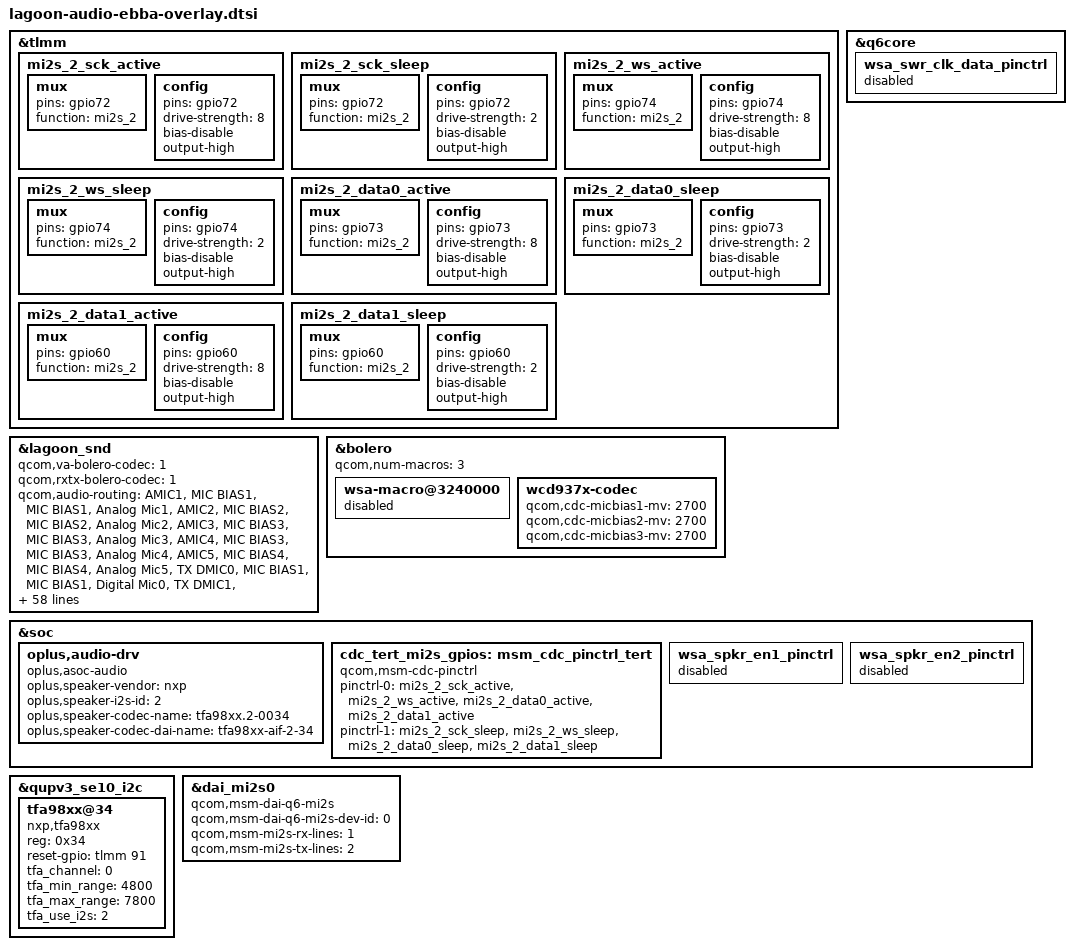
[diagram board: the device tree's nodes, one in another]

&tlmm {
		/* #ifdef OPLUS_ARCH_EXTENDS */
		mi2s_2_sck_active: mi2s_2_sck_active {
			mux {
					pins = "gpio72";
					function = "mi2s_2";
				};

				config {
					pins = "gpio72";
					drive-strength = <8>;	/* 8 mA */
					bias-disable;
					output-high;
				};
		};

		mi2s_2_sck_sleep: mi2s_2_sck_sleep {
			mux {
					pins = "gpio72";
					function = "mi2s_2";
				};

				config {
					pins = "gpio72";
					drive-strength = <2>;	/* 2 mA */
					bias-disable;
					output-high;
				};
		};

		mi2s_2_ws_active: mi2s_2_ws_active {
			mux {
					pins = "gpio74";
					function = "mi2s_2";
				};

				config {
					pins = "gpio74";
					drive-strength = <8>;	/* 8 mA */
					bias-disable;
					output-high;
				};
		};

		mi2s_2_ws_sleep: mi2s_2_ws_sleep {
			mux {
					pins = "gpio74";
					function = "mi2s_2";
				};

				config {
					pins = "gpio74";
					drive-strength = <2>;	/* 8 mA */
					bias-disable;
					output-high;
				};
		};

		mi2s_2_data0_active: mi2s_2_data0_active {
			mux {
					pins = "gpio73";
					function = "mi2s_2";
				};

				config {
					pins = "gpio73";
					drive-strength = <8>;	/* 8 mA */
					bias-disable;
					output-high;
				};
		};

		mi2s_2_data0_sleep: mi2s_2_data0_sleep {
			mux {
					pins = "gpio73";
					function = "mi2s_2";
				};

				config {
					pins = "gpio73";
					drive-strength = <2>;	/* 8 mA */
					bias-disable;
					output-high;
				};
		};

		mi2s_2_data1_active: mi2s_2_data1_active {
			mux {
					pins = "gpio60";
					function = "mi2s_2";
				};

				config {
					pins = "gpio60";
					drive-strength = <8>;	/* 8 mA */
					bias-disable;
					output-high;
				};
		};

		mi2s_2_data1_sleep: mi2s_2_data1_sleep {
			mux {
					pins = "gpio60";
					function = "mi2s_2";
				};

				config {
					pins = "gpio60";
					drive-strength = <2>;	/* 8 mA */
					bias-disable;
					output-high;
				};
		};
		//#endif /* OPLUS_ARCH_EXTENDS */
};

&q6core {
        wsa_swr_clk_data_pinctrl {
                status = "disabled";
        };
};

&lagoon_snd {
	qcom,va-bolero-codec = <1>;
	qcom,rxtx-bolero-codec = <1>;
	qcom,audio-routing =
		"AMIC1", "MIC BIAS1",
		"MIC BIAS1", "Analog Mic1",
		"AMIC2", "MIC BIAS2",
		"MIC BIAS2", "Analog Mic2",
		"AMIC3", "MIC BIAS3",
		"MIC BIAS3", "Analog Mic3",
		"AMIC4", "MIC BIAS3",
		"MIC BIAS3", "Analog Mic4",
		"AMIC5", "MIC BIAS4",
		"MIC BIAS4", "Analog Mic5",
		"TX DMIC0", "MIC BIAS1",
		"MIC BIAS1", "Digital Mic0",
		"TX DMIC1", "MIC BIAS1",
		"MIC BIAS1", "Digital Mic1",
		"TX DMIC2", "MIC BIAS3",
		"MIC BIAS3", "Digital Mic2",
		"TX DMIC3", "MIC BIAS3",
		"MIC BIAS3", "Digital Mic3",
		"TX DMIC4", "MIC BIAS4",
		"MIC BIAS4", "Digital Mic4",
		"TX DMIC5", "MIC BIAS4",
		"MIC BIAS4", "Digital Mic5",
		"IN1_HPHL", "HPHL_OUT",
		"IN2_HPHR", "HPHR_OUT",
		"IN3_AUX", "AUX_OUT",
		"TX SWR_ADC0", "ADC1_OUTPUT",
		//#ifdef OPLUS_ARCH_EXTENDS
		//for tfa98xx i2s
		"TX SWR_ADC2", "ADC2_OUTPUT",
		//#else /* OPLUS_ARCH_EXTENDS */
		//"TX SWR_ADC1", "ADC2_OUTPUT",
		//"TX SWR_ADC2", "ADC3_OUTPUT",
		//#endif /* OPLUS_ARCH_EXTENDS */
		"TX SWR_ADC3", "ADC4_OUTPUT",
		"TX SWR_DMIC0", "DMIC1_OUTPUT",
		"TX SWR_DMIC1", "DMIC2_OUTPUT",
		"TX SWR_DMIC2", "DMIC3_OUTPUT",
		"TX SWR_DMIC3", "DMIC4_OUTPUT",
		"TX SWR_DMIC4", "DMIC5_OUTPUT",
		"TX SWR_DMIC5", "DMIC6_OUTPUT",
		"TX SWR_DMIC6", "DMIC7_OUTPUT",
		"TX SWR_DMIC7", "DMIC8_OUTPUT",
		"WSA SRC0_INP", "SRC0",
		"WSA_TX DEC0_INP", "TX DEC0 MUX",
		"WSA_TX DEC1_INP", "TX DEC1 MUX",
		"RX_TX DEC0_INP", "TX DEC0 MUX",
		"RX_TX DEC1_INP", "TX DEC1 MUX",
		"RX_TX DEC2_INP", "TX DEC2 MUX",
		"RX_TX DEC3_INP", "TX DEC3 MUX",
		"SpkrLeft IN", "WSA_SPK1 OUT",
		"SpkrRight IN", "WSA_SPK2 OUT",
		"VA_AIF1 CAP", "VA_SWR_CLK",
		"VA_AIF2 CAP", "VA_SWR_CLK",
		"VA_AIF3 CAP", "VA_SWR_CLK",
		"VA MIC BIAS1", "Digital Mic0",
		"VA MIC BIAS1", "Digital Mic1",
		"VA MIC BIAS3", "Digital Mic2",
		"VA MIC BIAS3", "Digital Mic3",
		"VA MIC BIAS4", "Digital Mic4",
		"VA MIC BIAS4", "Digital Mic5",
		"VA DMIC0", "VA MIC BIAS1",
		"VA DMIC1", "VA MIC BIAS1",
		"VA DMIC2", "VA MIC BIAS3",
		"VA DMIC3", "VA MIC BIAS3",
		"VA DMIC4", "VA MIC BIAS4",
		"VA DMIC5", "VA MIC BIAS4",
		"VA SWR_ADC0", "VA_SWR_CLK",
		"VA SWR_ADC1", "VA_SWR_CLK",
		"VA SWR_ADC2", "VA_SWR_CLK",
		"VA SWR_ADC3", "VA_SWR_CLK",
		"VA SWR_MIC0", "VA_SWR_CLK",
		"VA SWR_MIC1", "VA_SWR_CLK",
		"VA SWR_MIC2", "VA_SWR_CLK",
		"VA SWR_MIC3", "VA_SWR_CLK",
		"VA SWR_MIC4", "VA_SWR_CLK",
		"VA SWR_MIC5", "VA_SWR_CLK",
		"VA SWR_MIC6", "VA_SWR_CLK",
		"VA SWR_MIC7", "VA_SWR_CLK",
		"VA SWR_ADC0", "ADC1_OUTPUT",
		//#ifdef OPLUS_ARCH_EXTENDS
		//for tfa98xx i2s
		"VA SWR_ADC2", "ADC2_OUTPUT",
		//#else /* OPLUS_ARCH_EXTENDS */
		//"VA SWR_ADC1", "ADC2_OUTPUT",
		//"VA SWR_ADC2", "ADC3_OUTPUT",
		//#endif /* OPLUS_ARCH_EXTENDS */
		"VA SWR_ADC3", "ADC4_OUTPUT",
		"VA SWR_MIC0", "DMIC1_OUTPUT",
		"VA SWR_MIC1", "DMIC2_OUTPUT",
		"VA SWR_MIC2", "DMIC3_OUTPUT",
		"VA SWR_MIC3", "DMIC4_OUTPUT",
		"VA SWR_MIC4", "DMIC5_OUTPUT",
		"VA SWR_MIC5", "DMIC6_OUTPUT",
		"VA SWR_MIC6", "DMIC7_OUTPUT",
		"VA SWR_MIC7", "DMIC8_OUTPUT";

        qcom,tert-mi2s-gpios = <&cdc_tert_mi2s_gpios>;

        qcom,wsa-max-devs = <0>;
        qcom,codec-max-aux-devs = <1>;
	
        qcom,msm-mbhc-hs-mic-max-threshold-mv = <2600>;
        qcom,msm-mbhc-hs-mic-min-threshold-mv = <75>;

        oplus,mbhc-check-cross-conn = <0>;

        qcom,mi2s-audio-intf = <1>;
        qcom,auxpcm-audio-intf = <1>;
        qcom,tdm-audio-intf = <1>;
        qcom,codec-aux-devs = <&wcd937x_codec>;

        oplus,mbhc-headset-bias-alwayon = <1>;
};

&bolero {
        qcom,num-macros = <3>;

        wsa-macro@3240000 {
                status = "disabled";
        };

        wcd937x-codec {
                qcom,cdc-micbias1-mv = <2700>;
                qcom,cdc-micbias2-mv = <2700>;
                qcom,cdc-micbias3-mv = <2700>;
        };
};

&soc {
        oplus,audio-drv {
                compatible = "oplus,asoc-audio";
                //for nxp speaker
                oplus,speaker-vendor = "nxp";
                oplus,speaker-i2s-id = <2>;
                oplus,speaker-codec-name = "tfa98xx.2-0034";
                oplus,speaker-codec-dai-name = "tfa98xx-aif-2-34";
        };

		cdc_tert_mi2s_gpios: msm_cdc_pinctrl_tert {
		compatible = "qcom,msm-cdc-pinctrl";
		status = "ok";
		pinctrl-names = "aud_active", "aud_sleep";
		pinctrl-0 = <&mi2s_2_sck_active &mi2s_2_ws_active
			 &mi2s_2_data0_active &mi2s_2_data1_active>;
		pinctrl-1 = <&mi2s_2_sck_sleep &mi2s_2_ws_sleep
			 &mi2s_2_data0_sleep &mi2s_2_data1_sleep>;
		};

        wsa_spkr_en1_pinctrl {
                status = "disabled";
        };
        wsa_spkr_en2_pinctrl {
                status = "disabled";
        };
};

&qupv3_se10_i2c {
	status = "okay";
#address-cells = <1>;
#size-cells = <0>;
	tfa98xx@34 {
		status = "okay";
		compatible = "nxp,tfa98xx";
		reg = <0x34>;
		reset-gpio =<&tlmm 91 0>;
		tfa_channel = <0>;
		tfa_min_range = <4800>;
		tfa_max_range = <7800>;
/*tfa_use_i2s: <0> pri; <1> sec; <2> tert; ...*/
		tfa_use_i2s = <2>;
	};
};

//Add for tfa98xx
&dai_mi2s0 {
        compatible = "qcom,msm-dai-q6-mi2s";
        qcom,msm-dai-q6-mi2s-dev-id = <0>;
        qcom,msm-mi2s-rx-lines = <1>;
        qcom,msm-mi2s-tx-lines = <2>;
};
